# K510 register map
Vendor: Canaan; File version: 1.0
Registers are 32-bit, read-write, reset 0x0 unless marked. A register's access mark holds for its fields unless they carry their own. Offsets are from the block's base; [hi:lo] are bit positions; lines under a group give offsets from that group; {n}, {i} and the like mark numbered series.

## GPIO — General Purpose I/O
Base 0x97050000
0x00 GPIO_SWPORTA_DR — data register
  [31:0] GPIO_SWPORTA_DR — Values written to this register are output on the I/O signals for Port A if the corresponding data direction bits for Port A are set to Output mode and the corresponding control bit for Port A is set to Software mode. The value read back is equal to the last value written to this register.
0x04 GPIO_SWPORTA_DDR — data direction
  [31:0] GPIO_SWPORTA_DDR — Values written to this register independently control the direction of the corresponding data bit in Port A. The default direction can be configured as input or output after system reset through the GPIO_DFLT_DIR_A parameter.
    0=INPUT (Input Direction); 1=OUTPUT (Output Direction)
0x08 GPIO_SWPORTA_CTL — data source control
  [0] GPIO_SWPORTA_CTL — The data and control source for a signal can come from either software or hardware; this bit selects between them.
0x30 GPIO_INTEN — interrupt enable
  [31:0] GPIO_INTEN — Allows each bit of Port A to be configured for interrupts. By default the generation of interrupts is disabled. Whenever a 1 is written to a bit of this register, it configures the corresponding bit on Port A to become an interrupt; otherwise, Port A operates as a normal GPIO signal. Interrupts are disabled on the corresponding bits of Port A if the corresponding data direction register is set to Output or if Port A mode is set to Hardware.
    0=DISABLE (Interrupt is disabled); 1=ENABLE (Interrupt is enabled)
0x34 GPIO_INTMASK — interrupt mask
  [31:0] GPIO_INTMASK — Controls whether an interrupt on Port A can create an interrupt for the interrupt controller by not masking it. By default, all interrupts bits are unmasked. Whenever a 1 is written to a bit in this register, it masks the interrupt generation capability for this signal; otherwise interrupts are allowed through. The unmasked status can be read as well as the resultant status after masking.
    0=DISABLE (Interrupt bits are unmasked); 1=ENABLE (Mask interrupt)
0x38 GPIO_INTTYPE_LEVEL — interrupt level
  [31:0] GPIO_INTTYPE_LEVEL — Controls the type of interrupt that can occur on Port A. Whenever a 0 is written to a bit of this register, it configures the interrupt type to be level- sensitive; otherwise, it is edgesensitive.
    0=LEVEL_SENSITIVE (Interrupt is level sensitive); 1=EDGE_SENSITIVE (Interrupt is edge sensitive)
0x3C GPIO_INT_POLARITY — interrupt polarity
  [31:0] GPIO_INT_POLARITY — Controls the polarity of edge or level sensitivity that can occur on input of Port A. Whenever a 0 is written to a bit of this register, it configures the interrupt type to falling-edge or active-low sensitive; otherwise, it is rising-edge or active-high sensitive.
    0=ACTIVE_LOW (Active Low polarity); 1=ACTIVE_HIGH (Active High polarity)
0x40 GPIO_INTSTATUS ro — interrupt status
  [31:0] GPIO_INTSTATUS — Interrupt status of Port A.
    0=INACTIVE; 1=ACTIVE
0x44 GPIO_RAW_INTSTATUS ro — raw interrupt status
  [31:0] GPIO_RAW_INTSTATUS — Raw interrupt status of Port A (premasking bits).
    0=INACTIVE; 1=ACTIVE
0x48 GPIO_DEBOUNCE — debounce enable
  [31:0] GPIO_DEBOUNCE — Controls whether an external signal that is the source of an interrupt needs to be debounced to remove any spurious glitches. Writing a 1 to a bit in this register enables the debouncing circuitry. A signal must be valid for two periods of an external clock before it is internally processed.
    0=DISABLE (Disable debounce); 1=ENABLE (Enable debounce)
0x4C GPIO_PORTA_EOI wo — end of interrupt
  [31:0] GPIO_PORTA_EOI — Controls the clearing of edge type interrupts from Port A. When a 1 is written into a corresponding bit of this register, the interrupt is cleared. All interrupts are cleared when Port A is not configured for interrupts.
    1=CLEAR (Clear interrupt)
0x50 GPIO_EXT_PORTA ro — external port
  [31:0] GPIO_EXT_PORTA — This register always reflects the signals value on the External Port A.
0x60 GPIO_LS_SYNC — synchronization level
0x64 GPIO_ID_CODE ro — ID info
  [31:0] GPIO_ID_CODE — This is a user-specified code that a system can read. It can be used for chip identification, and so on.
0x68 GPIO_INT_BOTHEDGE — interrupt edge type
  [31:0] GPIO_INT_BOTHEDGE — Controls the edge type of interrupt that can occur on Port A. Whenever a particular bit is programmed to 1, it enables the generation of interrupts on both the rising edge and the falling edge of an external input signal corresponding to that bit on port A. - The values programmed in the registers gpio_intype_level and gpio_int_polarity for this particular bit are not considered when the corresponding bit of this register is set to 1. - Whenever a particular bit is programmed to 0, the interrupt type depends on the value of the corresponding bits in the gpio_inttype_level and gpio_int_polarity registers.
    0=SINGLE_EDGE (Single Edge sensitive); 1=BOTH_EDGE (Both Edge sensitive)
0x6C GPIO_VER_ID_CODE ro — version info
  [31:0] GPIO_VER_ID_CODE — ASCII value for each number in the version, followed by *. For example 32_31_32_2A represents the version 2.12*.
0x70 GPIO_CONFIG_REG2 ro — parameters info
  [4:0] ENCODED_ID_PWIDTH_A — The value of this register is derived from the GPIO_PWIDTH_A configuration parameter
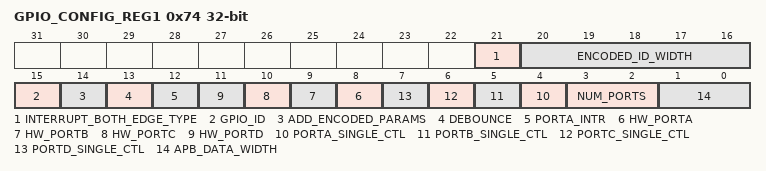
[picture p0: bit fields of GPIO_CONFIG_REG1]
0x74 GPIO_CONFIG_REG1 ro — parameters info
  [21] INTERRUPT_BOTH_EDGE_TYPE — The value of this register is derived from the GPIO_INT_BOTHEDGE configuration parameter
    0=SINGLE_EDGE (Interrupt generation on rising or falling edge); 1=BOTH_EDGE (Interrupt generation on both rising and falling edge)
  [20:16] ENCODED_ID_WIDTH — The value of this register is derived from the GPIO_ID_WIDTH configuration parameter.
  [15] GPIO_ID — The value of this register is derived from the GPIO_ID configuration parameter.
    0=NOT_INCLUDED (GPIO_ID not included); 1=INCLUDED (GPIO_ID included)
  [14] ADD_ENCODED_PARAMS — The value of this register is derived from the GPIO_ADD_ENCODED_PARAMS configuration parameter.
    0=NOT_ADDED (Encoded parameters not added); 1=ADDED (Encoded parameters added)
  [13] DEBOUNCE — The value of this register is derived from the GPIO_DEBOUNCE configuration parameter.
    0=EXCLUDE (Exclude debounce capability); 1=INCLUDE (Include debounce capability)
  [12] PORTA_INTR — The value of this register is derived from the GPIO_PORTA_INTR configuration parameter.
    0=DISABLED (PORT A is not used as an interrupt source); 1=ENABLED (PORT A is used as an interrupt source)
  [8] HW_PORT{x} (x=A,B,C,D; step 1) — The value of this register is derived from the GPIO_HW_PORT[ABCD] configuration parameter.
    0=EXCLUDED (PORT has external, auxiliary hardware signals excluded); 1=INCLUDED (PORT has external, auxiliary hardware signals included)
  [4] PORT{x}_SINGLE_CTL (x=A,B,C,D; step 1) — The value of this register is derived from the GPIO_PORT[ABCD]_SINGLE_CTL configuration parameter.
    0=NOT_SINGLE (PORT is not controlled from a single source); 1=SINGLE (PORT is controlled from a single source)
  [3:2] NUM_PORTS — The value of this register is derived from the GPIO_NUM_PORT configuration parameter.
    0=One port; 1=Two ports; 2=Three ports; 3=Four ports
  [1:0] APB_DATA_WIDTH — The value of this register is derived from the GPIO_APB_DATA_WIDTH configuration parameter.
    0=APB_8BITS (APB DATA WIDTH is 8 bits); 1=APB_16BITS (APB DATA WIDTH is 16 bits); 2=APB_32BITS (APB DATA WIDTH is 32 bits)

## PLIC — Platform-Level Interrupt Controller
Base 0x9EC00000
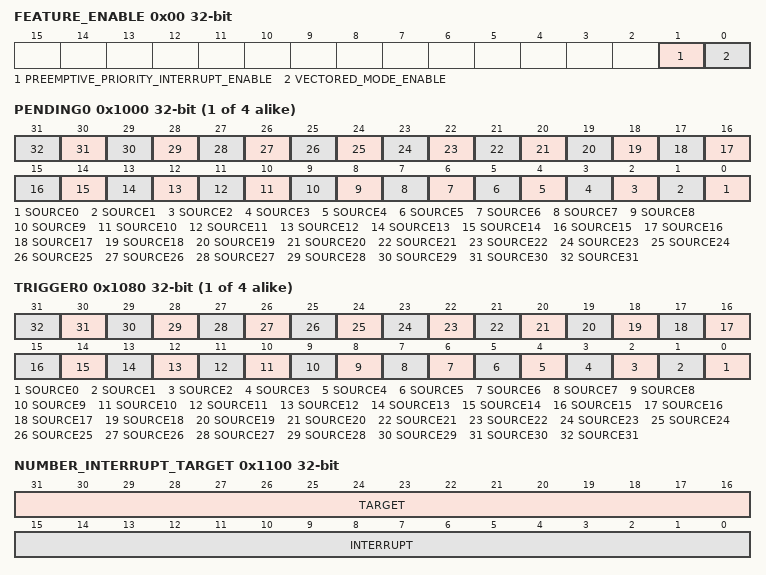
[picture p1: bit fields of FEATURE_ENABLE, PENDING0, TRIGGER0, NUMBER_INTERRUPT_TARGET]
0x00 FEATURE_ENABLE
  [1] PREEMPTIVE_PRIORITY_INTERRUPT_ENABLE
    0=DISABLED (Preemptive priority interrupt feature is Disabled); 1=ENABLED (Preemptive priority interrupt feature is Enabled)
  [0] VECTORED_MODE_ENABLE — Enable Vectored Mode for PLIC . AX25MP not support vector mode
    0=DISABLED (Vectored mode is Disabled); 1=ENABLED (Vectored mode is Enabled)
{0x0+4i} SOURCE{i}_PRIORITY (i=1..127) reset 0x1 (reset mask 0xF) — Priority Register for Source[i]
  [7:0] PRIORITY — Interrupt Source Priority
{0x1000+4i} PENDING{i} (i=0..3) — Souce[i:i+31] interrupt pending
  [n] SOURCE{n} (n=0..31) — Source[i] interrupt pending status
    0=NOT_PENDING (Source[i] interrupt is not pending); 1=PENDING (Source[i] interrupt is pending)
{0x1080+4i} TRIGGER{i} (i=0..3) — Souce[i:i+31] interrupt trigger type
  [n] SOURCE{n} (n=0..31) — Source[i] interrupt trigger type
    0=LEVEL (Level Triggered); 1=EDGE (Edge Triggered)
0x1100 NUMBER_INTERRUPT_TARGET ro — Number of interrupt and target configuration register
  [31:16] TARGET — Number of supported target
  [15:0] INTERRUPT — Number of supported interrupt
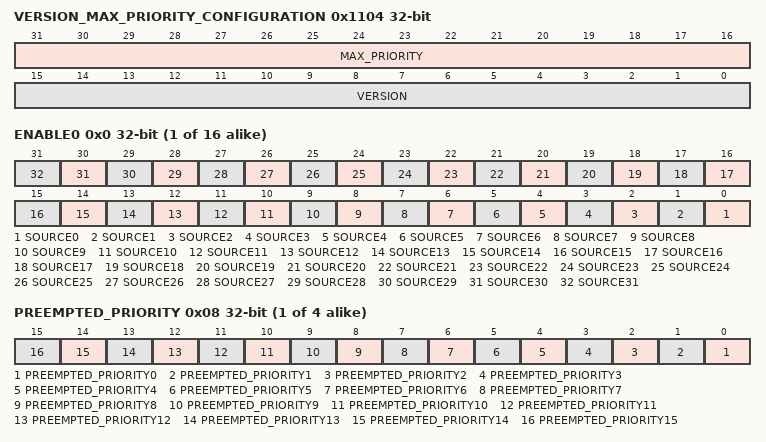
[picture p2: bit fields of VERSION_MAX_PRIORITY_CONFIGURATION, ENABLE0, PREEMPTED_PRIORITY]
0x1104 VERSION_MAX_PRIORITY_CONFIGURATION ro — Version and Maximum priority configuration register
  [31:16] MAX_PRIORITY — The maximum priority supported
  [15:0] VERSION — The version of the AndeStar V5 PLIC design
{0x2000+0x80*i} TARGET{i}_ENABLE (i=0..3) group — Target[M] enable registers
  {0x0+4j} ENABLE{j} (j=0..3) — Target[i:i+31] enable registers
    [n] SOURCE{n} (n=0..31) — SOURCE[i] enable status
      0=DISABLED (Target[i] is disabled); 1=ENABLED (Target[i] is enabled)
{0x200000+0x1000*i} CONTEXT{i} (i=0..3) group — Target[M]'s context: priority threshold, claim and complete, preempted priority
  0x00 THRESHOLD — Target[M]'s priority threshold register
    [15:0] THRESHOLD — Target[M]'s priority threshold
  0x04 CLAIM_COMPLETE — Target[M]'s claim and complete register
    [15:0] CLAIM_COMPLETE range 0..127 — Target[M]'s claim and complete
  0x08 PREEMPTED_PRIORITY — Target[M]'s preempted priority register provide the preempted priority stack information for each target
    [n] PREEMPTED_PRIORITY{n} (n=0..15) — Target[M]'s preempted priority[P]
      0=NO_PREEMPTED (This priority no preempted by a higher priority interrupt); 1=PREEMPTED (This priority has been preempted by a higher priority interrupt)
